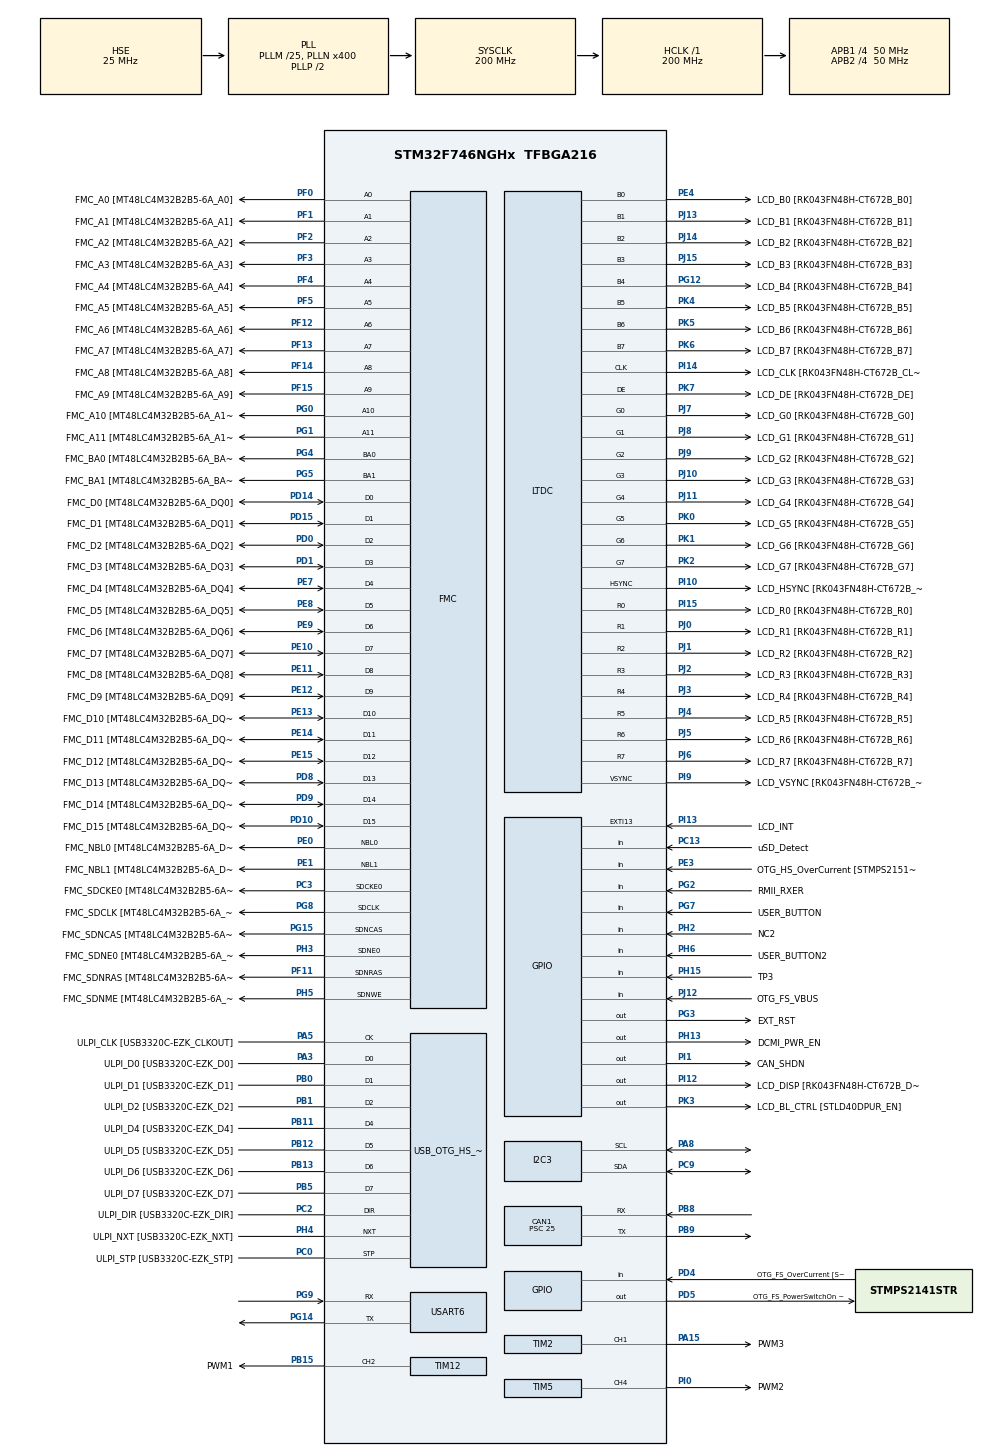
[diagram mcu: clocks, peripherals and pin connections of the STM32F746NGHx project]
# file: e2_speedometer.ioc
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CAN1.BS1=CAN_BS1_6TQ
CAN1.CalculateBaudRate=250000
CAN1.CalculateTimeBit=4000
CAN1.CalculateTimeQuantum=500.0
CAN1.Mode=CAN_MODE_NORMAL
CAN1.Prescaler=25
CAN1.RFLM=DISABLE
I2C3.Timing=0x00C0EAFF
Mcu.Family=STM32F7
Mcu.Name=STM32F746NGHx
Mcu.Package=TFBGA216
NVIC.CAN1_RX0_IRQn=true\:0\:0\:false\:true\:true\:1\:true\:true\:true
NVIC.PriorityGroup=NVIC_PRIORITYGROUP_4
NVIC.TIM6_DAC_IRQn=true\:15\:0\:true\:false\:true\:false\:true\:true
NVIC.TIM8_TRG_COM_TIM14_IRQn=true\:0\:0\:false\:false\:true\:true\:true\:true
NVIC.TIM8_UP_TIM13_IRQn=true\:0\:0\:false\:false\:true\:true\:true\:true
NVIC.TimeBase=TIM6_DAC_IRQn
NVIC.TimeBaseIP=TIM6
PA13.GPIO_Label=SWDIO
PA13.Mode=Serial_Wire
PA13.Signal=SYS_JTMS-SWDIO
PA14.GPIO_Label=SWCLK
PA14.Mode=Serial_Wire
PA14.Signal=SYS_JTCK-SWCLK
PA15.GPIO_Label=PWM3
PA15.GPIO_ModeDefaultPP=GPIO_MODE_AF_PP
PA15.GPIO_PuPd=GPIO_NOPULL
PA15.GPIO_Speed=GPIO_SPEED_FREQ_LOW
PA15.Signal=S_TIM2_CH1_ETR
PA3.GPIO_Label=ULPI_D0 [USB3320C-EZK_D0]
PA3.Mode=Host_HS
PA3.Signal=USB_OTG_HS_ULPI_D0
PA5.GPIO_Label=ULPI_CLK [USB3320C-EZK_CLKOUT]
PA5.Mode=Host_HS
PA5.Signal=USB_OTG_HS_ULPI_CK
PA8.Mode=I2C
PA8.Signal=I2C3_SCL
PB0.GPIO_Label=ULPI_D1 [USB3320C-EZK_D1]
PB0.Mode=Host_HS
PB0.Signal=USB_OTG_HS_ULPI_D1
PB1.GPIO_Label=ULPI_D2 [USB3320C-EZK_D2]
PB1.Mode=Host_HS
PB1.Signal=USB_OTG_HS_ULPI_D2
PB11.GPIO_Label=ULPI_D4 [USB3320C-EZK_D4]
PB11.Mode=Host_HS
PB11.Signal=USB_OTG_HS_ULPI_D4
PB12.GPIO_Label=ULPI_D5 [USB3320C-EZK_D5]
PB12.Mode=Host_HS
PB12.Signal=USB_OTG_HS_ULPI_D5
PB13.GPIO_Label=ULPI_D6 [USB3320C-EZK_D6]
PB13.Mode=Host_HS
PB13.Signal=USB_OTG_HS_ULPI_D6
PB15.GPIO_Label=PWM1
PB15.Signal=S_TIM12_CH2
PB5.GPIO_Label=ULPI_D7 [USB3320C-EZK_D7]
PB5.Mode=Host_HS
PB5.Signal=USB_OTG_HS_ULPI_D7
PB8.Mode=CAN_Activate
PB8.Signal=CAN1_RX
PB9.Mode=CAN_Activate
PB9.Signal=CAN1_TX
PC0.GPIO_Label=ULPI_STP [USB3320C-EZK_STP]
PC0.Mode=Host_HS
PC0.Signal=USB_OTG_HS_ULPI_STP
PC13.GPIO_Label=uSD_Detect
PC13.Signal=GPIO_Input
PC14/OSC32_IN.GPIO_Label=RCC_OSC32_IN
PC14/OSC32_IN.Mode=LSE-External-Oscillator
PC14/OSC32_IN.Signal=RCC_OSC32_IN
PC15/OSC32_OUT.GPIO_Label=RCC_OSC32_OUT
PC15/OSC32_OUT.Mode=LSE-External-Oscillator
PC15/OSC32_OUT.Signal=RCC_OSC32_OUT
PC2.GPIO_Label=ULPI_DIR [USB3320C-EZK_DIR]
PC2.Mode=Host_HS
PC2.Signal=USB_OTG_HS_ULPI_DIR
PC3.GPIO_Label=FMC_SDCKE0 [MT48LC4M32B2B5-6A_CKE]
PC3.Mode=SdramChipSelect1_1
PC3.Signal=FMC_SDCKE0
PC9.Mode=I2C
PC9.Signal=I2C3_SDA
PD0.GPIO_Label=FMC_D2 [MT48LC4M32B2B5-6A_DQ2]
PD0.Signal=FMC_D2_DA2
PD1.GPIO_Label=FMC_D3 [MT48LC4M32B2B5-6A_DQ3]
PD1.Signal=FMC_D3_DA3
PD10.GPIO_Label=FMC_D15 [MT48LC4M32B2B5-6A_DQ15]
PD10.Signal=FMC_D15_DA15
PD14.GPIO_Label=FMC_D0 [MT48LC4M32B2B5-6A_DQ0]
PD14.Signal=FMC_D0_DA0
PD15.GPIO_Label=FMC_D1 [MT48LC4M32B2B5-6A_DQ1]
PD15.Signal=FMC_D1_DA1
PD4.GPIO_Label=OTG_FS_OverCurrent [STMPS2141STR_Fault]
PD4.Signal=GPIO_Input
PD5.GPIO_Label=OTG_FS_PowerSwitchOn [STMPS2141STR_EN]
PD5.PinState=GPIO_PIN_SET
PD5.Signal=GPIO_Output
PD8.GPIO_Label=FMC_D13 [MT48LC4M32B2B5-6A_DQ13]
PD8.Signal=FMC_D13_DA13
PD9.GPIO_Label=FMC_D14 [MT48LC4M32B2B5-6A_DQ14]
PD9.Signal=FMC_D14_DA14
PE0.GPIO_Label=FMC_NBL0 [MT48LC4M32B2B5-6A_DQM0]
PE0.Signal=FMC_NBL0
PE1.GPIO_Label=FMC_NBL1 [MT48LC4M32B2B5-6A_DQM1]
PE1.Signal=FMC_NBL1
PE10.GPIO_Label=FMC_D7 [MT48LC4M32B2B5-6A_DQ7]
PE10.Signal=FMC_D7_DA7
PE11.GPIO_Label=FMC_D8 [MT48LC4M32B2B5-6A_DQ8]
PE11.Signal=FMC_D8_DA8
PE12.GPIO_Label=FMC_D9 [MT48LC4M32B2B5-6A_DQ9]
PE12.Signal=FMC_D9_DA9
PE13.GPIO_Label=FMC_D10 [MT48LC4M32B2B5-6A_DQ10]
PE13.Signal=FMC_D10_DA10
PE14.GPIO_Label=FMC_D11 [MT48LC4M32B2B5-6A_DQ11]
PE14.Signal=FMC_D11_DA11
PE15.GPIO_Label=FMC_D12 [MT48LC4M32B2B5-6A_DQ12]
PE15.Signal=FMC_D12_DA12
PE3.GPIO_Label=OTG_HS_OverCurrent [STMPS2151STR_FAULT]
PE3.Signal=GPIO_Input
PE4.GPIO_Label=LCD_B0 [RK043FN48H-CT672B_B0]
PE4.Mode=RGB888
PE4.Signal=LTDC_B0
PE7.GPIO_Label=FMC_D4 [MT48LC4M32B2B5-6A_DQ4]
PE7.Signal=FMC_D4_DA4
PE8.GPIO_Label=FMC_D5 [MT48LC4M32B2B5-6A_DQ5]
PE8.Signal=FMC_D5_DA5
PE9.GPIO_Label=FMC_D6 [MT48LC4M32B2B5-6A_DQ6]
PE9.Signal=FMC_D6_DA6
PF0.GPIO_Label=FMC_A0 [MT48LC4M32B2B5-6A_A0]
PF0.Signal=FMC_A0
PF1.GPIO_Label=FMC_A1 [MT48LC4M32B2B5-6A_A1]
PF1.Signal=FMC_A1
PF11.GPIO_Label=FMC_SDNRAS [MT48LC4M32B2B5-6A_RAS]
PF11.Signal=FMC_SDNRAS
PF12.GPIO_Label=FMC_A6 [MT48LC4M32B2B5-6A_A6]
PF12.Signal=FMC_A6
PF13.GPIO_Label=FMC_A7 [MT48LC4M32B2B5-6A_A7]
PF13.Signal=FMC_A7
PF14.GPIO_Label=FMC_A8 [MT48LC4M32B2B5-6A_A8]
PF14.Signal=FMC_A8
PF15.GPIO_Label=FMC_A9 [MT48LC4M32B2B5-6A_A9]
PF15.Signal=FMC_A9
PF2.GPIO_Label=FMC_A2 [MT48LC4M32B2B5-6A_A2]
PF2.Signal=FMC_A2
PF3.GPIO_Label=FMC_A3 [MT48LC4M32B2B5-6A_A3]
PF3.Signal=FMC_A3
PF4.GPIO_Label=FMC_A4 [MT48LC4M32B2B5-6A_A4]
PF4.Signal=FMC_A4
PF5.GPIO_Label=FMC_A5 [MT48LC4M32B2B5-6A_A5]
PF5.Signal=FMC_A5
PG0.GPIO_Label=FMC_A10 [MT48LC4M32B2B5-6A_A10]
PG0.Signal=FMC_A10
PG1.GPIO_Label=FMC_A11 [MT48LC4M32B2B5-6A_A11]
PG1.Signal=FMC_A11
PG12.GPIO_Label=LCD_B4 [RK043FN48H-CT672B_B4]
PG12.Mode=RGB888
PG12.Signal=LTDC_B4
PG14.Mode=Asynchronous
PG14.Signal=USART6_TX
PG15.GPIO_Label=FMC_SDNCAS [MT48LC4M32B2B5-6A_CAS]
PG15.Signal=FMC_SDNCAS
PG2.GPIO_Label=RMII_RXER
PG2.Signal=GPIO_Input
PG3.GPIO_Label=EXT_RST
PG3.Signal=GPIO_Output
PG4.GPIO_Label=FMC_BA0 [MT48LC4M32B2B5-6A_BA0]
PG4.Signal=FMC_A14_BA0
PG5.GPIO_Label=FMC_BA1 [MT48LC4M32B2B5-6A_BA1]
PG5.Signal=FMC_A15_BA1
PG7.GPIO_Label=USER_BUTTON
PG7.Signal=GPIO_Input
PG8.GPIO_Label=FMC_SDCLK [MT48LC4M32B2B5-6A_CLK]
PG8.Signal=FMC_SDCLK
PG9.Mode=Asynchronous
PG9.Signal=USART6_RX
PH0/OSC_IN.GPIO_Label=OSC_25M [NZ2520SB-25.00M_OUT]
PH0/OSC_IN.Mode=HSE-External-Oscillator
PH0/OSC_IN.Signal=RCC_OSC_IN
PH1/OSC_OUT.Mode=HSE-External-Oscillator
PH1/OSC_OUT.Signal=RCC_OSC_OUT
PH13.GPIO_Label=DCMI_PWR_EN
PH13.Signal=GPIO_Output
PH15.GPIO_Label=TP3
PH15.Signal=GPIO_Input
PH2.GPIO_Label=NC2
PH2.Signal=GPIO_Input
PH3.GPIO_Label=FMC_SDNE0 [MT48LC4M32B2B5-6A_CS]
PH3.Mode=SdramChipSelect1_1
PH3.Signal=FMC_SDNE0
PH4.GPIO_Label=ULPI_NXT [USB3320C-EZK_NXT]
PH4.Mode=Host_HS
PH4.Signal=USB_OTG_HS_ULPI_NXT
PH5.GPIO_Label=FMC_SDNME [MT48LC4M32B2B5-6A_WE]
PH5.Signal=FMC_SDNWE
PH6.GPIO_Label=USER_BUTTON2
PH6.Signal=GPIO_Input
PI0.GPIO_Label=PWM2
PI0.Signal=S_TIM5_CH4
PI1.GPIO_Label=CAN_SHDN
PI1.Signal=GPIO_Output
PI10.GPIO_Label=LCD_HSYNC [RK043FN48H-CT672B_HSYNC]
PI10.Mode=RGB888
PI10.Signal=LTDC_HSYNC
PI12.GPIO_Label=LCD_DISP [RK043FN48H-CT672B_DISP] 
PI12.PinState=GPIO_PIN_SET
PI12.Signal=GPIO_Output
PI13.GPIO_Label=LCD_INT
PI13.GPIO_ModeDefaultEXTI=GPIO_MODE_EVT_RISING
PI13.Signal=GPXTI13
PI14.GPIO_Label=LCD_CLK [RK043FN48H-CT672B_CLK]
PI14.Mode=RGB888
PI14.Signal=LTDC_CLK
PI15.GPIO_Label=LCD_R0 [RK043FN48H-CT672B_R0]
PI15.Mode=RGB888
PI15.Signal=LTDC_R0
PI9.GPIO_Label=LCD_VSYNC [RK043FN48H-CT672B_VSYNC]
PI9.Mode=RGB888
PI9.Signal=LTDC_VSYNC
PJ0.GPIO_Label=LCD_R1 [RK043FN48H-CT672B_R1]
PJ0.Mode=RGB888
PJ0.Signal=LTDC_R1
PJ1.GPIO_Label=LCD_R2 [RK043FN48H-CT672B_R2]
PJ1.Mode=RGB888
PJ1.Signal=LTDC_R2
PJ10.GPIO_Label=LCD_G3 [RK043FN48H-CT672B_G3]
PJ10.Mode=RGB888
PJ10.Signal=LTDC_G3
PJ11.GPIO_Label=LCD_G4 [RK043FN48H-CT672B_G4]
PJ11.Mode=RGB888
PJ11.Signal=LTDC_G4
PJ12.GPIO_Label=OTG_FS_VBUS
PJ12.Signal=GPIO_Input
PJ13.GPIO_Label=LCD_B1 [RK043FN48H-CT672B_B1]
PJ13.Mode=RGB888
PJ13.Signal=LTDC_B1
PJ14.GPIO_Label=LCD_B2 [RK043FN48H-CT672B_B2]
PJ14.Mode=RGB888
PJ14.Signal=LTDC_B2
PJ15.GPIO_Label=LCD_B3 [RK043FN48H-CT672B_B3]
PJ15.Mode=RGB888
PJ15.Signal=LTDC_B3
PJ2.GPIO_Label=LCD_R3 [RK043FN48H-CT672B_R3]
PJ2.Mode=RGB888
PJ2.Signal=LTDC_R3
PJ3.GPIO_Label=LCD_R4 [RK043FN48H-CT672B_R4]
PJ3.Mode=RGB888
PJ3.Signal=LTDC_R4
PJ4.GPIO_Label=LCD_R5 [RK043FN48H-CT672B_R5]
PJ4.Mode=RGB888
PJ4.Signal=LTDC_R5
PJ5.GPIO_Label=LCD_R6 [RK043FN48H-CT672B_R6]
PJ5.Mode=RGB888
PJ5.Signal=LTDC_R6
PJ6.GPIO_Label=LCD_R7 [RK043FN48H-CT672B_R7]
PJ6.Mode=RGB888
PJ6.Signal=LTDC_R7
PJ7.GPIO_Label=LCD_G0 [RK043FN48H-CT672B_G0]
PJ7.Mode=RGB888
PJ7.Signal=LTDC_G0
PJ8.GPIO_Label=LCD_G1 [RK043FN48H-CT672B_G1]
PJ8.Mode=RGB888
PJ8.Signal=LTDC_G1
PJ9.GPIO_Label=LCD_G2 [RK043FN48H-CT672B_G2]
PJ9.Mode=RGB888
PJ9.Signal=LTDC_G2
PK0.GPIO_Label=LCD_G5 [RK043FN48H-CT672B_G5]
PK0.Mode=RGB888
PK0.Signal=LTDC_G5
PK1.GPIO_Label=LCD_G6 [RK043FN48H-CT672B_G6]
PK1.Mode=RGB888
PK1.Signal=LTDC_G6
PK2.GPIO_Label=LCD_G7 [RK043FN48H-CT672B_G7]
PK2.Mode=RGB888
PK2.Signal=LTDC_G7
PK3.GPIO_Label=LCD_BL_CTRL [STLD40DPUR_EN]
PK3.GPIO_Speed=GPIO_SPEED_FREQ_LOW
PK3.PinState=GPIO_PIN_SET
PK3.Signal=GPIO_Output
PK4.GPIO_Label=LCD_B5 [RK043FN48H-CT672B_B5]
PK4.Mode=RGB888
PK4.Signal=LTDC_B5
PK5.GPIO_Label=LCD_B6 [RK043FN48H-CT672B_B6]
PK5.Mode=RGB888
PK5.Signal=LTDC_B6
PK6.GPIO_Label=LCD_B7 [RK043FN48H-CT672B_B7]
PK6.Mode=RGB888
PK6.Signal=LTDC_B7
PK7.GPIO_Label=LCD_DE [RK043FN48H-CT672B_DE]
PK7.Mode=RGB888
PK7.Signal=LTDC_DE
ProjectManager.HeapSize=0x200
ProjectManager.StackSize=0x400
ProjectManager.TargetToolchain=STM32CubeIDE
RCC.AHBFreq_Value=200000000
RCC.APB1CLKDivider=RCC_HCLK_DIV4
RCC.APB1Freq_Value=50000000
RCC.APB1TimFreq_Value=100000000
RCC.APB2CLKDivider=RCC_HCLK_DIV4
RCC.APB2Freq_Value=50000000
RCC.APB2TimFreq_Value=100000000
RCC.CortexFreq_Value=200000000
RCC.HCLKFreq_Value=200000000
RCC.HSE_VALUE=25000000
RCC.HSI_VALUE=16000000
RCC.PLL48CLockSelection=RCC_CLK48SOURCE_PLLSAIP
RCC.PLLI2SN=100
RCC.PLLM=25
RCC.PLLN=400
RCC.PLLQ=9
RCC.PLLSAIN=384
RCC.PLLSAIP=RCC_PLLSAIP_DIV8
RCC.PLLSAIR=5
RCC.PLLSAIRDiv=RCC_PLLSAIDIVR_8
RCC.PLLSourceVirtual=RCC_PLLSOURCE_HSE
RCC.SDMMCClockSelection=RCC_SDMMC1CLKSOURCE_CLK48
RCC.SYSCLKFreq_VALUE=200000000
RCC.SYSCLKSource=RCC_SYSCLKSOURCE_PLLCLK
RCC.USBFreq_Value=48000000
RCC.VCOOutputFreq_Value=400000000
SH.FMC_A0.0=FMC_A0,12b-sda1
SH.FMC_A1.0=FMC_A1,12b-sda1
SH.FMC_A10.0=FMC_A10,12b-sda1
SH.FMC_A11.0=FMC_A11,12b-sda1
SH.FMC_A14_BA0.0=FMC_BA0,FourSdramBanks1
SH.FMC_A15_BA1.0=FMC_BA1,FourSdramBanks1
SH.FMC_A2.0=FMC_A2,12b-sda1
SH.FMC_A3.0=FMC_A3,12b-sda1
SH.FMC_A4.0=FMC_A4,12b-sda1
SH.FMC_A5.0=FMC_A5,12b-sda1
SH.FMC_A6.0=FMC_A6,12b-sda1
SH.FMC_A7.0=FMC_A7,12b-sda1
SH.FMC_A8.0=FMC_A8,12b-sda1
SH.FMC_A9.0=FMC_A9,12b-sda1
SH.FMC_D0_DA0.0=FMC_D0,sd-16b-d1
SH.FMC_D10_DA10.0=FMC_D10,sd-16b-d1
SH.FMC_D11_DA11.0=FMC_D11,sd-16b-d1
SH.FMC_D12_DA12.0=FMC_D12,sd-16b-d1
SH.FMC_D13_DA13.0=FMC_D13,sd-16b-d1
SH.FMC_D14_DA14.0=FMC_D14,sd-16b-d1
SH.FMC_D15_DA15.0=FMC_D15,sd-16b-d1
SH.FMC_D1_DA1.0=FMC_D1,sd-16b-d1
SH.FMC_D2_DA2.0=FMC_D2,sd-16b-d1
SH.FMC_D3_DA3.0=FMC_D3,sd-16b-d1
SH.FMC_D4_DA4.0=FMC_D4,sd-16b-d1
SH.FMC_D5_DA5.0=FMC_D5,sd-16b-d1
SH.FMC_D6_DA6.0=FMC_D6,sd-16b-d1
SH.FMC_D7_DA7.0=FMC_D7,sd-16b-d1
SH.FMC_D8_DA8.0=FMC_D8,sd-16b-d1
SH.FMC_D9_DA9.0=FMC_D9,sd-16b-d1
SH.FMC_NBL0.0=FMC_NBL0,Sd2ByteEnable1
SH.FMC_NBL1.0=FMC_NBL1,Sd2ByteEnable1
SH.FMC_SDCLK.0=FMC_SDCLK,12b-sda1
SH.FMC_SDNCAS.0=FMC_SDNCAS,12b-sda1
SH.FMC_SDNRAS.0=FMC_SDNRAS,12b-sda1
SH.FMC_SDNWE.0=FMC_SDNWE,12b-sda1
SH.S_TIM12_CH2.0=TIM12_CH2,PWM Generation2 CH2
SH.S_TIM2_CH1_ETR.0=TIM2_CH1,PWM Generation1 CH1
SH.S_TIM5_CH4.0=TIM5_CH4,PWM Generation4 CH4
TIM12.Channel-PWM\ Generation2\ CH2=TIM_CHANNEL_2
TIM13.AutoReloadPreload=TIM_AUTORELOAD_PRELOAD_ENABLE
TIM13.Period=1000
TIM13.Prescaler=99
TIM14.AutoReloadPreload=TIM_AUTORELOAD_PRELOAD_ENABLE
TIM14.Period=10000
TIM14.Prescaler=9999
TIM2.Channel-PWM\ Generation1\ CH1=TIM_CHANNEL_1
TIM5.Channel-PWM\ Generation4\ CH4=TIM_CHANNEL_4
USART6.VirtualMode-Asynchronous=VM_ASYNC
VP_DMA2D_VS_DMA2D.Mode=DMA2D_Activate
VP_SYS_VS_tim6.Mode=TIM6
VP_TIM13_VS_ClockSourceINT.Mode=Enable_Timer
VP_TIM14_VS_ClockSourceINT.Mode=Enable_Timer
VP_TIM2_VS_ClockSourceINT.Mode=Internal
VP_TIM5_VS_ClockSourceINT.Mode=Internal
board=STM32F746G-DISCO

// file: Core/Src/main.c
/* USER CODE BEGIN Header */
/**
  ******************************************************************************
  * @file           : main.c
  * @brief          : Main program body
  ******************************************************************************
  * @attention
  *
  * Copyright (c) 2022 STMicroelectronics.
  * All rights reserved.
  *
  * This software is licensed under terms that can be found in the LICENSE file
  * in the root directory of this software component.
  * If no LICENSE file comes with this software, it is provided AS-IS.
  *
  ******************************************************************************
  */
/* USER CODE END Header */
#include "main.h"

/* USER CODE BEGIN Includes */
#include "car.h"
#include "gui.h"
#include "can.h"
#include "timers.h"
#include "E2_Frames.h"
#include "../Utilities/BSP/stm32746g_discovery_lcd.h"
#include "../Utilities/BSP/stm32746g_discovery_ts.h"
#include <string.h>
/* USER CODE END Includes */

CAN_HandleTypeDef hcan1;

DMA2D_HandleTypeDef hdma2d;

I2C_HandleTypeDef hi2c3;

LTDC_HandleTypeDef hltdc;

TIM_HandleTypeDef htim2;
TIM_HandleTypeDef htim5;
TIM_HandleTypeDef htim12;
TIM_HandleTypeDef htim13;
TIM_HandleTypeDef htim14;

UART_HandleTypeDef huart6;

SDRAM_HandleTypeDef hsdram1;

/* USER CODE BEGIN PV */

carInfo_t carInfo;

/* USER CODE END PV */

void SystemClock_Config(void);
static void MX_GPIO_Init(void);
static void MX_DMA2D_Init(void);
static void MX_FMC_Init(void);
static void MX_LTDC_Init(void);
static void MX_TIM2_Init(void);
static void MX_TIM5_Init(void);
static void MX_TIM12_Init(void);
static void MX_CAN1_Init(void);
static void MX_TIM14_Init(void);
static void MX_I2C3_Init(void);
static void MX_USART6_UART_Init(void);
static void MX_TIM13_Init(void);
static void MX_NVIC_Init(void);

int main(void)
{

  /* MCU Configuration--------------------------------------------------------*/

  /* Reset of all peripherals, Initializes the Flash interface and the Systick. */
  HAL_Init();

  /* Configure the system clock */
  SystemClock_Config();

  /* Initialize all configured peripherals */
  MX_GPIO_Init();
  MX_DMA2D_Init();
  MX_FMC_Init();
  MX_LTDC_Init();
  MX_TIM2_Init();
  MX_TIM5_Init();
  MX_TIM12_Init();
  MX_CAN1_Init();
  MX_TIM14_Init();
  MX_I2C3_Init();
  MX_USART6_UART_Init();
  MX_TIM13_Init();

  /* Initialize interrupts */
  MX_NVIC_Init();
  /* USER CODE BEGIN 2 */
  memset(&carInfo,0,sizeof(carInfo_t));

// I2C to the touch sensor is occupied by CAN in current hw configuration
//  TS_StatusTypeDef status = BSP_TS_Init(BSP_LCD_GetXSize(), BSP_LCD_GetXSize());
//  TS_StateTypeDef touch;

  TIM_InitCallbackList();

  GUI_Init(30, &htim14);
  CAN_Init(&hcan1, &htim13);
  /* USER CODE END 2 */

  /* Infinite loop */
  while (1)
  {

  }
}

void SystemClock_Config(void)
{
  RCC_OscInitTypeDef RCC_OscInitStruct = {0};
  RCC_ClkInitTypeDef RCC_ClkInitStruct = {0};

  /** Configure LSE Drive Capability
  */
  HAL_PWR_EnableBkUpAccess();

  /** Configure the main internal regulator output voltage
  */
  __HAL_RCC_PWR_CLK_ENABLE();
  __HAL_PWR_VOLTAGESCALING_CONFIG(PWR_REGULATOR_VOLTAGE_SCALE1);

  /** Initializes the RCC Oscillators according to the specified parameters
  * in the RCC_OscInitTypeDef structure.
  */
  RCC_OscInitStruct.OscillatorType = RCC_OSCILLATORTYPE_HSE;
  RCC_OscInitStruct.HSEState = RCC_HSE_ON;
  RCC_OscInitStruct.PLL.PLLState = RCC_PLL_ON;
  RCC_OscInitStruct.PLL.PLLSource = RCC_PLLSOURCE_HSE;
  RCC_OscInitStruct.PLL.PLLM = 25;
  RCC_OscInitStruct.PLL.PLLN = 400;
  RCC_OscInitStruct.PLL.PLLP = RCC_PLLP_DIV2;
  RCC_OscInitStruct.PLL.PLLQ = 9;
  if (HAL_RCC_OscConfig(&RCC_OscInitStruct) != HAL_OK)
  {
    Error_Handler();
  }

  /** Activate the Over-Drive mode
  */
  if (HAL_PWREx_EnableOverDrive() != HAL_OK)
  {
    Error_Handler();
  }

  /** Initializes the CPU, AHB and APB buses clocks
  */
  RCC_ClkInitStruct.ClockType = RCC_CLOCKTYPE_HCLK|RCC_CLOCKTYPE_SYSCLK
                              |RCC_CLOCKTYPE_PCLK1|RCC_CLOCKTYPE_PCLK2;
  RCC_ClkInitStruct.SYSCLKSource = RCC_SYSCLKSOURCE_PLLCLK;
  RCC_ClkInitStruct.AHBCLKDivider = RCC_SYSCLK_DIV1;
  RCC_ClkInitStruct.APB1CLKDivider = RCC_HCLK_DIV4;
  RCC_ClkInitStruct.APB2CLKDivider = RCC_HCLK_DIV4;

  if (HAL_RCC_ClockConfig(&RCC_ClkInitStruct, FLASH_LATENCY_6) != HAL_OK)
  {
    Error_Handler();
  }
}

/**
  * @brief NVIC Configuration.
  * @retval None
  */
static void MX_NVIC_Init(void)
{
  /* CAN1_RX0_IRQn interrupt configuration */
  HAL_NVIC_SetPriority(CAN1_RX0_IRQn, 0, 0);
  HAL_NVIC_EnableIRQ(CAN1_RX0_IRQn);
}

static void MX_CAN1_Init(void)
{

  hcan1.Instance = CAN1;
  hcan1.Init.Prescaler = 25;
  hcan1.Init.Mode = CAN_MODE_NORMAL;
  hcan1.Init.SyncJumpWidth = CAN_SJW_1TQ;
  hcan1.Init.TimeSeg1 = CAN_BS1_6TQ;
  hcan1.Init.TimeSeg2 = CAN_BS2_1TQ;
  hcan1.Init.TimeTriggeredMode = DISABLE;
  hcan1.Init.AutoBusOff = DISABLE;
  hcan1.Init.AutoWakeUp = DISABLE;
  hcan1.Init.AutoRetransmission = DISABLE;
  hcan1.Init.ReceiveFifoLocked = DISABLE;
  hcan1.Init.TransmitFifoPriority = DISABLE;
  if (HAL_CAN_Init(&hcan1) != HAL_OK)
  {
    Error_Handler();
  }

}

static void MX_DMA2D_Init(void)
{

  hdma2d.Instance = DMA2D;
  hdma2d.Init.Mode = DMA2D_M2M;
  hdma2d.Init.ColorMode = DMA2D_OUTPUT_ARGB8888;
  hdma2d.Init.OutputOffset = 0;
  hdma2d.LayerCfg[1].InputOffset = 0;
  hdma2d.LayerCfg[1].InputColorMode = DMA2D_INPUT_ARGB8888;
  hdma2d.LayerCfg[1].AlphaMode = DMA2D_NO_MODIF_ALPHA;
  hdma2d.LayerCfg[1].InputAlpha = 0;
  if (HAL_DMA2D_Init(&hdma2d) != HAL_OK)
  {
    Error_Handler();
  }
  if (HAL_DMA2D_ConfigLayer(&hdma2d, 1) != HAL_OK)
  {
    Error_Handler();
  }

}

static void MX_I2C3_Init(void)
{

  hi2c3.Instance = I2C3;
  hi2c3.Init.Timing = 0x00C0EAFF;
  hi2c3.Init.OwnAddress1 = 0;
  hi2c3.Init.AddressingMode = I2C_ADDRESSINGMODE_7BIT;
  hi2c3.Init.DualAddressMode = I2C_DUALADDRESS_DISABLE;
  hi2c3.Init.OwnAddress2 = 0;
  hi2c3.Init.OwnAddress2Masks = I2C_OA2_NOMASK;
  hi2c3.Init.GeneralCallMode = I2C_GENERALCALL_DISABLE;
  hi2c3.Init.NoStretchMode = I2C_NOSTRETCH_DISABLE;
  if (HAL_I2C_Init(&hi2c3) != HAL_OK)
  {
    Error_Handler();
  }

  /** Configure Analogue filter
  */
  if (HAL_I2CEx_ConfigAnalogFilter(&hi2c3, I2C_ANALOGFILTER_ENABLE) != HAL_OK)
  {
    Error_Handler();
  }

  /** Configure Digital filter
  */
  if (HAL_I2CEx_ConfigDigitalFilter(&hi2c3, 0) != HAL_OK)
  {
    Error_Handler();
  }

}

static void MX_LTDC_Init(void)
{

  LTDC_LayerCfgTypeDef pLayerCfg = {0};
  LTDC_LayerCfgTypeDef pLayerCfg1 = {0};

  hltdc.Instance = LTDC;
  hltdc.Init.HSPolarity = LTDC_HSPOLARITY_AL;
  hltdc.Init.VSPolarity = LTDC_VSPOLARITY_AL;
  hltdc.Init.DEPolarity = LTDC_DEPOLARITY_AL;
  hltdc.Init.PCPolarity = LTDC_PCPOLARITY_IPC;
  hltdc.Init.HorizontalSync = 7;
  hltdc.Init.VerticalSync = 3;
  hltdc.Init.AccumulatedHBP = 14;
  hltdc.Init.AccumulatedVBP = 5;
  hltdc.Init.AccumulatedActiveW = 654;
  hltdc.Init.AccumulatedActiveH = 485;
  hltdc.Init.TotalWidth = 660;
  hltdc.Init.TotalHeigh = 487;
  hltdc.Init.Backcolor.Blue = 0;
  hltdc.Init.Backcolor.Green = 0;
  hltdc.Init.Backcolor.Red = 0;
  if (HAL_LTDC_Init(&hltdc) != HAL_OK)
  {
    Error_Handler();
  }
  pLayerCfg.WindowX0 = 0;
  pLayerCfg.WindowX1 = 0;
  pLayerCfg.WindowY0 = 0;
  pLayerCfg.WindowY1 = 0;
  pLayerCfg.PixelFormat = LTDC_PIXEL_FORMAT_ARGB8888;
  pLayerCfg.Alpha = 0;
  pLayerCfg.Alpha0 = 0;
  pLayerCfg.BlendingFactor1 = LTDC_BLENDING_FACTOR1_CA;
  pLayerCfg.BlendingFactor2 = LTDC_BLENDING_FACTOR2_CA;
  pLayerCfg.FBStartAdress = 0;
  pLayerCfg.ImageWidth = 0;
  pLayerCfg.ImageHeight = 0;
  pLayerCfg.Backcolor.Blue = 0;
  pLayerCfg.Backcolor.Green = 0;
  pLayerCfg.Backcolor.Red = 0;
  if (HAL_LTDC_ConfigLayer(&hltdc, &pLayerCfg, 0) != HAL_OK)
  {
    Error_Handler();
  }
  pLayerCfg1.WindowX0 = 0;
  pLayerCfg1.WindowX1 = 0;
  pLayerCfg1.WindowY0 = 0;
  pLayerCfg1.WindowY1 = 0;
  pLayerCfg1.PixelFormat = LTDC_PIXEL_FORMAT_ARGB8888;
  pLayerCfg1.Alpha = 0;
  pLayerCfg1.Alpha0 = 0;
  pLayerCfg1.BlendingFactor1 = LTDC_BLENDING_FACTOR1_CA;
  pLayerCfg1.BlendingFactor2 = LTDC_BLENDING_FACTOR2_CA;
  pLayerCfg1.FBStartAdress = 0;
  pLayerCfg1.ImageWidth = 0;
  pLayerCfg1.ImageHeight = 0;
  pLayerCfg1.Backcolor.Blue = 0;
  pLayerCfg1.Backcolor.Green = 0;
  pLayerCfg1.Backcolor.Red = 0;
  if (HAL_LTDC_ConfigLayer(&hltdc, &pLayerCfg1, 1) != HAL_OK)
  {
    Error_Handler();
  }

}

static void MX_TIM2_Init(void)
{

  TIM_ClockConfigTypeDef sClockSourceConfig = {0};
  TIM_MasterConfigTypeDef sMasterConfig = {0};
  TIM_OC_InitTypeDef sConfigOC = {0};

  htim2.Instance = TIM2;
  htim2.Init.Prescaler = 0;
  htim2.Init.CounterMode = TIM_COUNTERMODE_UP;
  htim2.Init.Period = 4294967295;
  htim2.Init.ClockDivision = TIM_CLOCKDIVISION_DIV1;
  htim2.Init.AutoReloadPreload = TIM_AUTORELOAD_PRELOAD_DISABLE;
  if (HAL_TIM_Base_Init(&htim2) != HAL_OK)
  {
    Error_Handler();
  }
  sClockSourceConfig.ClockSource = TIM_CLOCKSOURCE_INTERNAL;
  if (HAL_TIM_ConfigClockSource(&htim2, &sClockSourceConfig) != HAL_OK)
  {
    Error_Handler();
  }
  if (HAL_TIM_PWM_Init(&htim2) != HAL_OK)
  {
    Error_Handler();
  }
  sMasterConfig.MasterOutputTrigger = TIM_TRGO_RESET;
  sMasterConfig.MasterSlaveMode = TIM_MASTERSLAVEMODE_DISABLE;
  if (HAL_TIMEx_MasterConfigSynchronization(&htim2, &sMasterConfig) != HAL_OK)
  {
    Error_Handler();
  }
  sConfigOC.OCMode = TIM_OCMODE_PWM1;
  sConfigOC.Pulse = 0;
  sConfigOC.OCPolarity = TIM_OCPOLARITY_HIGH;
  sConfigOC.OCFastMode = TIM_OCFAST_DISABLE;
  if (HAL_TIM_PWM_ConfigChannel(&htim2, &sConfigOC, TIM_CHANNEL_1) != HAL_OK)
  {
    Error_Handler();
  }
  HAL_TIM_MspPostInit(&htim2);

}

static void MX_TIM5_Init(void)
{

  TIM_ClockConfigTypeDef sClockSourceConfig = {0};
  TIM_MasterConfigTypeDef sMasterConfig = {0};
  TIM_OC_InitTypeDef sConfigOC = {0};

  htim5.Instance = TIM5;
  htim5.Init.Prescaler = 0;
  htim5.Init.CounterMode = TIM_COUNTERMODE_UP;
  htim5.Init.Period = 4294967295;
  htim5.Init.ClockDivision = TIM_CLOCKDIVISION_DIV1;
  htim5.Init.AutoReloadPreload = TIM_AUTORELOAD_PRELOAD_DISABLE;
  if (HAL_TIM_Base_Init(&htim5) != HAL_OK)
  {
    Error_Handler();
  }
  sClockSourceConfig.ClockSource = TIM_CLOCKSOURCE_INTERNAL;
  if (HAL_TIM_ConfigClockSource(&htim5, &sClockSourceConfig) != HAL_OK)
  {
    Error_Handler();
  }
  if (HAL_TIM_PWM_Init(&htim5) != HAL_OK)
  {
    Error_Handler();
  }
  sMasterConfig.MasterOutputTrigger = TIM_TRGO_RESET;
  sMasterConfig.MasterSlaveMode = TIM_MASTERSLAVEMODE_DISABLE;
  if (HAL_TIMEx_MasterConfigSynchronization(&htim5, &sMasterConfig) != HAL_OK)
  {
    Error_Handler();
  }
  sConfigOC.OCMode = TIM_OCMODE_PWM1;
  sConfigOC.Pulse = 0;
  sConfigOC.OCPolarity = TIM_OCPOLARITY_HIGH;
  sConfigOC.OCFastMode = TIM_OCFAST_DISABLE;
  if (HAL_TIM_PWM_ConfigChannel(&htim5, &sConfigOC, TIM_CHANNEL_4) != HAL_OK)
  {
    Error_Handler();
  }
  HAL_TIM_MspPostInit(&htim5);

}

static void MX_TIM12_Init(void)
{

  TIM_OC_InitTypeDef sConfigOC = {0};

  htim12.Instance = TIM12;
  htim12.Init.Prescaler = 0;
  htim12.Init.CounterMode = TIM_COUNTERMODE_UP;
  htim12.Init.Period = 65535;
  htim12.Init.ClockDivision = TIM_CLOCKDIVISION_DIV1;
  htim12.Init.AutoReloadPreload = TIM_AUTORELOAD_PRELOAD_DISABLE;
  if (HAL_TIM_PWM_Init(&htim12) != HAL_OK)
  {
    Error_Handler();
  }
  sConfigOC.OCMode = TIM_OCMODE_PWM1;
  sConfigOC.Pulse = 0;
  sConfigOC.OCPolarity = TIM_OCPOLARITY_HIGH;
  sConfigOC.OCFastMode = TIM_OCFAST_DISABLE;
  if (HAL_TIM_PWM_ConfigChannel(&htim12, &sConfigOC, TIM_CHANNEL_2) != HAL_OK)
  {
    Error_Handler();
  }
  HAL_TIM_MspPostInit(&htim12);

}

static void MX_TIM13_Init(void)
{

  htim13.Instance = TIM13;
  htim13.Init.Prescaler = 99;
  htim13.Init.CounterMode = TIM_COUNTERMODE_UP;
  htim13.Init.Period = 1000;
  htim13.Init.ClockDivision = TIM_CLOCKDIVISION_DIV1;
  htim13.Init.AutoReloadPreload = TIM_AUTORELOAD_PRELOAD_ENABLE;
  if (HAL_TIM_Base_Init(&htim13) != HAL_OK)
  {
    Error_Handler();
  }

}

static void MX_TIM14_Init(void)
{

  htim14.Instance = TIM14;
  htim14.Init.Prescaler = 9999;
  htim14.Init.CounterMode = TIM_COUNTERMODE_UP;
  htim14.Init.Period = 10000;
  htim14.Init.ClockDivision = TIM_CLOCKDIVISION_DIV1;
  htim14.Init.AutoReloadPreload = TIM_AUTORELOAD_PRELOAD_ENABLE;
  if (HAL_TIM_Base_Init(&htim14) != HAL_OK)
  {
    Error_Handler();
  }

}

static void MX_USART6_UART_Init(void)
{

  huart6.Instance = USART6;
  huart6.Init.BaudRate = 115200;
  huart6.Init.WordLength = UART_WORDLENGTH_8B;
  huart6.Init.StopBits = UART_STOPBITS_1;
  huart6.Init.Parity = UART_PARITY_NONE;
  huart6.Init.Mode = UART_MODE_TX_RX;
  huart6.Init.HwFlowCtl = UART_HWCONTROL_NONE;
  huart6.Init.OverSampling = UART_OVERSAMPLING_16;
  huart6.Init.OneBitSampling = UART_ONE_BIT_SAMPLE_DISABLE;
  huart6.AdvancedInit.AdvFeatureInit = UART_ADVFEATURE_NO_INIT;
  if (HAL_UART_Init(&huart6) != HAL_OK)
  {
    Error_Handler();
  }

}

/* FMC initialization function */
static void MX_FMC_Init(void)
{

  FMC_SDRAM_TimingTypeDef SdramTiming = {0};

  /** Perform the SDRAM1 memory initialization sequence
  */
  hsdram1.Instance = FMC_SDRAM_DEVICE;
  /* hsdram1.Init */
  hsdram1.Init.SDBank = FMC_SDRAM_BANK1;
  hsdram1.Init.ColumnBitsNumber = FMC_SDRAM_COLUMN_BITS_NUM_8;
  hsdram1.Init.RowBitsNumber = FMC_SDRAM_ROW_BITS_NUM_12;
  hsdram1.Init.MemoryDataWidth = FMC_SDRAM_MEM_BUS_WIDTH_16;
  hsdram1.Init.InternalBankNumber = FMC_SDRAM_INTERN_BANKS_NUM_4;
  hsdram1.Init.CASLatency = FMC_SDRAM_CAS_LATENCY_1;
  hsdram1.Init.WriteProtection = FMC_SDRAM_WRITE_PROTECTION_DISABLE;
  hsdram1.Init.SDClockPeriod = FMC_SDRAM_CLOCK_DISABLE;
  hsdram1.Init.ReadBurst = FMC_SDRAM_RBURST_DISABLE;
  hsdram1.Init.ReadPipeDelay = FMC_SDRAM_RPIPE_DELAY_0;
  /* SdramTiming */
  SdramTiming.LoadToActiveDelay = 16;
  SdramTiming.ExitSelfRefreshDelay = 16;
  SdramTiming.SelfRefreshTime = 16;
  SdramTiming.RowCycleDelay = 16;
  SdramTiming.WriteRecoveryTime = 16;
  SdramTiming.RPDelay = 16;
  SdramTiming.RCDDelay = 16;

  if (HAL_SDRAM_Init(&hsdram1, &SdramTiming) != HAL_OK)
  {
    Error_Handler( );
  }

}

static void MX_GPIO_Init(void)
{
  GPIO_InitTypeDef GPIO_InitStruct = {0};

  /* GPIO Ports Clock Enable */
  __HAL_RCC_GPIOE_CLK_ENABLE();
  __HAL_RCC_GPIOG_CLK_ENABLE();
  __HAL_RCC_GPIOB_CLK_ENABLE();
  __HAL_RCC_GPIOA_CLK_ENABLE();
  __HAL_RCC_GPIOJ_CLK_ENABLE();
  __HAL_RCC_GPIOD_CLK_ENABLE();
  __HAL_RCC_GPIOK_CLK_ENABLE();
  __HAL_RCC_GPIOC_CLK_ENABLE();
  __HAL_RCC_GPIOF_CLK_ENABLE();
  __HAL_RCC_GPIOI_CLK_ENABLE();
  __HAL_RCC_GPIOH_CLK_ENABLE();

  /*Configure GPIO pin Output Level */
  HAL_GPIO_WritePin(OTG_FS_PowerSwitchOn_GPIO_Port, OTG_FS_PowerSwitchOn_Pin, GPIO_PIN_SET);

  /*Configure GPIO pin Output Level */
  HAL_GPIO_WritePin(LCD_BL_CTRL_GPIO_Port, LCD_BL_CTRL_Pin, GPIO_PIN_SET);

  /*Configure GPIO pin Output Level */
  HAL_GPIO_WritePin(CAN_SHDN_GPIO_Port, CAN_SHDN_Pin, GPIO_PIN_RESET);

  /*Configure GPIO pin Output Level */
  HAL_GPIO_WritePin(LCD_DISP_GPIO_Port, LCD_DISP_Pin, GPIO_PIN_SET);

  /*Configure GPIO pin Output Level */
  HAL_GPIO_WritePin(DCMI_PWR_EN_GPIO_Port, DCMI_PWR_EN_Pin, GPIO_PIN_RESET);

  /*Configure GPIO pin Output Level */
  HAL_GPIO_WritePin(EXT_RST_GPIO_Port, EXT_RST_Pin, GPIO_PIN_RESET);

  /*Configure GPIO pin : OTG_HS_OverCurrent_Pin */
  GPIO_InitStruct.Pin = OTG_HS_OverCurrent_Pin;
  GPIO_InitStruct.Mode = GPIO_MODE_INPUT;
  GPIO_InitStruct.Pull = GPIO_NOPULL;
  HAL_GPIO_Init(OTG_HS_OverCurrent_GPIO_Port, &GPIO_InitStruct);

  /*Configure GPIO pins : ULPI_D7_Pin ULPI_D6_Pin ULPI_D5_Pin ULPI_D2_Pin
                           ULPI_D1_Pin ULPI_D4_Pin */
  GPIO_InitStruct.Pin = ULPI_D7_Pin|ULPI_D6_Pin|ULPI_D5_Pin|ULPI_D2_Pin
                          |ULPI_D1_Pin|ULPI_D4_Pin;
  GPIO_InitStruct.Mode = GPIO_MODE_AF_PP;
  GPIO_InitStruct.Pull = GPIO_NOPULL;
  GPIO_InitStruct.Speed = GPIO_SPEED_FREQ_VERY_HIGH;
  GPIO_InitStruct.Alternate = GPIO_AF10_OTG_HS;
  HAL_GPIO_Init(GPIOB, &GPIO_InitStruct);

  /*Configure GPIO pin : OTG_FS_VBUS_Pin */
  GPIO_InitStruct.Pin = OTG_FS_VBUS_Pin;
  GPIO_InitStruct.Mode = GPIO_MODE_INPUT;
  GPIO_InitStruct.Pull = GPIO_NOPULL;
  HAL_GPIO_Init(OTG_FS_VBUS_GPIO_Port, &GPIO_InitStruct);

  /*Configure GPIO pin : OTG_FS_PowerSwitchOn_Pin */
  GPIO_InitStruct.Pin = OTG_FS_PowerSwitchOn_Pin;
  GPIO_InitStruct.Mode = GPIO_MODE_OUTPUT_PP;
  GPIO_InitStruct.Pull = GPIO_NOPULL;
  GPIO_InitStruct.Speed = GPIO_SPEED_FREQ_LOW;
  HAL_GPIO_Init(OTG_FS_PowerSwitchOn_GPIO_Port, &GPIO_InitStruct);

  /*Configure GPIO pin : uSD_Detect_Pin */
  GPIO_InitStruct.Pin = uSD_Detect_Pin;
  GPIO_InitStruct.Mode = GPIO_MODE_INPUT;
  GPIO_InitStruct.Pull = GPIO_NOPULL;
  HAL_GPIO_Init(uSD_Detect_GPIO_Port, &GPIO_InitStruct);

  /*Configure GPIO pin : LCD_BL_CTRL_Pin */
  GPIO_InitStruct.Pin = LCD_BL_CTRL_Pin;
  GPIO_InitStruct.Mode = GPIO_MODE_OUTPUT_PP;
  GPIO_InitStruct.Pull = GPIO_NOPULL;
  GPIO_InitStruct.Speed = GPIO_SPEED_FREQ_LOW;
  HAL_GPIO_Init(LCD_BL_CTRL_GPIO_Port, &GPIO_InitStruct);

  /*Configure GPIO pin : OTG_FS_OverCurrent_Pin */
  GPIO_InitStruct.Pin = OTG_FS_OverCurrent_Pin;
  GPIO_InitStruct.Mode = GPIO_MODE_INPUT;
  GPIO_InitStruct.Pull = GPIO_NOPULL;
  HAL_GPIO_Init(OTG_FS_OverCurrent_GPIO_Port, &GPIO_InitStruct);

  /*Configure GPIO pins : TP3_Pin NC2_Pin */
  GPIO_InitStruct.Pin = TP3_Pin|NC2_Pin;
  GPIO_InitStruct.Mode = GPIO_MODE_INPUT;
  GPIO_InitStruct.Pull = GPIO_NOPULL;
  HAL_GPIO_Init(GPIOH, &GPIO_InitStruct);

  /*Configure GPIO pins : CAN_SHDN_Pin LCD_DISP_Pin */
  GPIO_InitStruct.Pin = CAN_SHDN_Pin|LCD_DISP_Pin;
  GPIO_InitStruct.Mode = GPIO_MODE_OUTPUT_PP;
  GPIO_InitStruct.Pull = GPIO_NOPULL;
  GPIO_InitStruct.Speed = GPIO_SPEED_FREQ_LOW;
  HAL_GPIO_Init(GPIOI, &GPIO_InitStruct);

  /*Configure GPIO pin : DCMI_PWR_EN_Pin */
  GPIO_InitStruct.Pin = DCMI_PWR_EN_Pin;
  GPIO_InitStruct.Mode = GPIO_MODE_OUTPUT_PP;
  GPIO_InitStruct.Pull = GPIO_NOPULL;
  GPIO_InitStruct.Speed = GPIO_SPEED_FREQ_LOW;
  HAL_GPIO_Init(DCMI_PWR_EN_GPIO_Port, &GPIO_InitStruct);

  /*Configure GPIO pin : LCD_INT_Pin */
  GPIO_InitStruct.Pin = LCD_INT_Pin;
  GPIO_InitStruct.Mode = GPIO_MODE_EVT_RISING;
  GPIO_InitStruct.Pull = GPIO_NOPULL;
  HAL_GPIO_Init(LCD_INT_GPIO_Port, &GPIO_InitStruct);

  /*Configure GPIO pin : ULPI_NXT_Pin */
  GPIO_InitStruct.Pin = ULPI_NXT_Pin;
  GPIO_InitStruct.Mode = GPIO_MODE_AF_PP;
  GPIO_InitStruct.Pull = GPIO_NOPULL;
  GPIO_InitStruct.Speed = GPIO_SPEED_FREQ_VERY_HIGH;
  GPIO_InitStruct.Alternate = GPIO_AF10_OTG_HS;
  HAL_GPIO_Init(ULPI_NXT_GPIO_Port, &GPIO_InitStruct);

  /*Configure GPIO pins : ULPI_STP_Pin ULPI_DIR_Pin */
  GPIO_InitStruct.Pin = ULPI_STP_Pin|ULPI_DIR_Pin;
  GPIO_InitStruct.Mode = GPIO_MODE_AF_PP;
  GPIO_InitStruct.Pull = GPIO_NOPULL;
  GPIO_InitStruct.Speed = GPIO_SPEED_FREQ_VERY_HIGH;
  GPIO_InitStruct.Alternate = GPIO_AF10_OTG_HS;
  HAL_GPIO_Init(GPIOC, &GPIO_InitStruct);

  /*Configure GPIO pin : EXT_RST_Pin */
  GPIO_InitStruct.Pin = EXT_RST_Pin;
  GPIO_InitStruct.Mode = GPIO_MODE_OUTPUT_PP;
  GPIO_InitStruct.Pull = GPIO_NOPULL;
  GPIO_InitStruct.Speed = GPIO_SPEED_FREQ_LOW;
  HAL_GPIO_Init(EXT_RST_GPIO_Port, &GPIO_InitStruct);

  /*Configure GPIO pin : RMII_RXER_Pin */
  GPIO_InitStruct.Pin = RMII_RXER_Pin;
  GPIO_InitStruct.Mode = GPIO_MODE_INPUT;
  GPIO_InitStruct.Pull = GPIO_NOPULL;
  HAL_GPIO_Init(RMII_RXER_GPIO_Port, &GPIO_InitStruct);

  /*Configure GPIO pins : ULPI_CLK_Pin ULPI_D0_Pin */
  GPIO_InitStruct.Pin = ULPI_CLK_Pin|ULPI_D0_Pin;
  GPIO_InitStruct.Mode = GPIO_MODE_AF_PP;
  GPIO_InitStruct.Pull = GPIO_NOPULL;
  GPIO_InitStruct.Speed = GPIO_SPEED_FREQ_VERY_HIGH;
  GPIO_InitStruct.Alternate = GPIO_AF10_OTG_HS;
  HAL_GPIO_Init(GPIOA, &GPIO_InitStruct);

}

void Error_Handler(void)
{
  __disable_irq();
  while (1)
  {
  }
}
